# BlueNRG1 register map
Vendor: STMicroelectronics; Series: BlueNRG1; File version: 2.2.1
ARM 32-bit Cortex-M0 Microcontroller based device, CPU clock up to 32MHz
CPU: CM0 r0p0, little endian, no MPU, no FPU, 2 interrupt priority bits
Registers are 32-bit, read-write, reset 0x0 unless marked. A register's access mark holds for its fields unless they carry their own. Offsets are from the block's base; lines under a group give offsets from that group; [hi:lo] are bit positions; {n}, {i} and the like mark numbered series; 'fields as' and 'values as' point back to an identical list; <NAME> marks a mode.

## Memory map
0x10000000 ROM_INFO size 0x800 — ROM information
0x40000000 GPIO size 0x1000 — GPIO Controller
0x40100000 FLASH size 0x1000 — Flash Controller
0x40200000 SYSTEM_CTRL size 0x1000 — System controller
0x40300000 UART size 0x1000
0x40400000 SPI size 0x1000 — Serial peripheral interface
0x40700000 WDG size 0x1000 — Watchdog
0x40800000 ADC size 0x1000
0x40900000 CKGEN_SOC size 0x1000 — Clock Gen SOC
0x40A00000 I2C2 size 0x1000
0x40B00000 I2C1 size 0x1000
0x40C00000 AHBUPCONV size 0x1000 — AHB up/down converter converter
0x40D00000 MFT1 size 0x1000
0x40E00000 MFT2 size 0x1000
0x40F00000 RTC size 0x1000 — Real-Time Counter
0x48000000 BLUE_CTRL size 0x1000 — BLUE Controller
0x48100000 CKGEN_BLE size 0x1000 — Clock Gen BLE
0xA0000000 DMA size 0x8
0xA0000008 DMA_CH0 size 0x10 — DMA channel
0xA000001C DMA_CH1 size 0x10
0xA0000030 DMA_CH2 size 0x10
0xA0000044 DMA_CH3 size 0x10
0xA0000058 DMA_CH4 size 0x10
0xA000006C DMA_CH5 size 0x10
0xA0000080 DMA_CH6 size 0x10
0xA0000094 DMA_CH7 size 0x10
0xB0000000 RNG size 0x1000
0xC0000000 PKA size 0x1000

## Interrupts
0 GPIO — GPIO bus interrupt
1 NVM (FLASH) — Non-volatile memory (Flash) controller interrupt
4 UART — UART interrupt
5 SPI — SPI interrupt
6 BLUE_CTRL — BLUE controller interrupt
7 WDG — Watchdog interrupt
13 ADC — ADC interrupt
14 I2C2 — I2C 2 interrupt
15 I2C1 — I2C 1 interrupt
17 MFT1A (MFT1) — Multi functional timer MFT1 interrupt A
18 MFT1B (MFT1) — Multi functional timer MFT1 interrupt B
19 MFT2A (MFT2) — Multi functional timer MFT2 interrupt A
20 MFT2B (MFT2) — Multi functional timer MFT2 interrupt B
21 RTC — RTC interrupt
22 PKA — PKA interrupt
23 DMA — DMA interrupt

## GPIO — GPIO Controller
Base 0x40000000
0x00 DATA (reset mask 0x3FFFFFF) — IO0 to IO14 data value.<p>Writing to a bit will drive the written value on the corresponding IO when it is configured in GPIO mode and the output direction. Reading a bit indicates the pin value</p>
0x04 OEN (reset mask 0x3FFFFFF) — GPIO output enable register (1 bit per GPIO).<ul><li>0: input mode.</li><li>1: output mode</li></ul>
0x08 PE reset 0x3FFFFFF (reset mask 0x3FFFFFF) — Pull enable (1 bit per IO).<ul><li>0: pull disabled.</li><li>1: pull enabled</li></ul>
0x0C DS (reset mask 0x3FFFFFF) — IO driver strength (1 bit per IO).<ul><li>0: 2mA.</li><li>1: 4 mA</li></ul>
0x10 IS (reset mask 0x3FFFFFF) — Interrupt sense register (1 bit per IO).<ul><li>0: edge detection.</li><li>1: level detection</li></ul>
0x14 IBE (reset mask 0x3FFFFFF) — Interrupt edge register (1 bit per IO).<ul><li>0: single edge.</li><li>1: both edges</li></ul>
0x18 IEV (reset mask 0x3FFFFFF) — Interrupt event register (1 bit per IO).<ul><li>0: falling edge or low level.</li><li>1: rising edge or high level</li></ul>
0x1C IE (reset mask 0x3FFFFFF) — Interrupt mask register (1 bit per IO).<ul><li>0: interrupt disabled.</li><li>1: interrupt enabled.</li></ul>
0x20 RIS ro (reset mask 0x3FFFFFF) — Raw interrupt status register (1 bit per IO)
0x24 MIS ro (reset mask 0x3FFFFFF) — Masked interrupt status register (1 bit per IO)
0x28 IC wo (reset mask 0x3FFFFFF) write-1-clears — Interrupt clear register (1 bit per IO).<ul><li>0: no effect.</li><li>1: clear interrupt</li></ul>
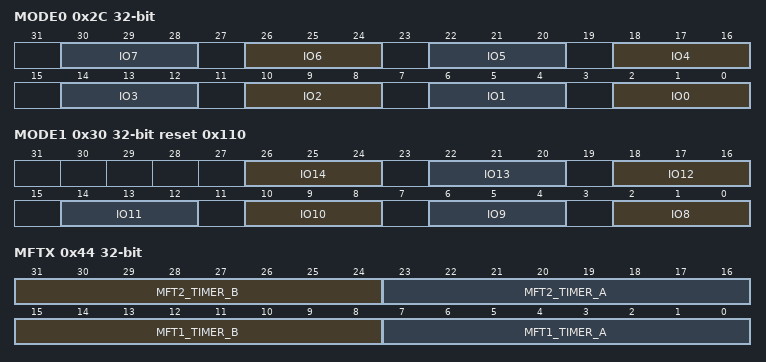
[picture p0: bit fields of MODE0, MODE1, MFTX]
0x2C MODE0 — Select mode for IO0 to IO7.<ul><li>000b: GPIO mode.</li><li>001b: Serial1 mode.</li><li>100b: Serial0 mode.</li><li>101b: Microphone/ADC mode.</li></ul>
  [all] fields
    0=GPIO_MODE; 1=SERIAL1_MODE; 2=STANDALONE_MODE; 3=BLUE_MODE (BLE mode); 4=SERIAL0_MODE; 5=MICROPHONE_ADC_MODE (ADC mode for microphone)
  [4n+2:4n] IO{n} (n=0..7) — IO{n} mode
0x30 MODE1 reset 0x110 — Select mode for IO8 to IO14.<ul><li>000b: GPIO mode.</li><li>001b: Serial1 mode.</li><li>100b: Serial0 mode.</li><li>101b: Microphone/ADC mode.</li></ul>
  [all] fields
    values as the fields of MODE0
  [4n-30:4n-32] IO{n} (n=8..14) — IO{n} mode
0x3C DATS (reset mask 0x3FFFFFF) — Set some bits of DATA when in GPIO mode without affecting the others (1 bit per IO).<ul><li>0: no effect.</li><li>1: set at 1 the bit</li></ul>
0x40 DATC (reset mask 0x3FFFFFF) — Clear some bits of DATA when in GPIO mode without affecting the others (1 bit per IO).<ul><li>0: no effect.</li><li>1: clear at 0 the bit</li></ul>
0x44 MFTX — Select the IO to be used as capture input for the MFTX timers
  [all] fields
    {v}=IO{v} (v=0..25)
  [31:24] MFT2_TIMER_B — Selects which IO must be used as input pin TnB for the MFT2 peripheral. Only mode 2 and mode 4.<ul><li>0x00: IO0.</li><li>0x01: IO1</li><li>0x02: IO2</li><li>...</li><li>0x0E: IO14</li></ul>
  [23:16] MFT2_TIMER_A — Selects which IO must be used as input pin TnA for the MFT2 peripheral. Only mode 2 and mode 4.<ul><li>0x00: IO0.</li><li>0x01: IO1</li><li>0x02: IO2</li><li>...</li><li>0x0E: IO14</li></ul>
  [15:8] MFT1_TIMER_B — Selects which IO must be used as input pin TnB for the MFT1 peripheral. Only mode 2 and mode 4.<ul><li>0x00: IO0.</li><li>0x01: IO1</li><li>0x02: IO2</li><li>...</li><li>0x0E: IO14</li></ul>
  [7:0] MFT1_TIMER_A — Selects which IO must be used as input pin TnA for the MFT1 peripheral. Only mode 2 and mode 4.<ul><li>0x00: IO0.</li><li>0x01: IO1</li><li>0x02: IO2</li><li>...</li><li>0x0E: IO14</li></ul>

## Licence text in the file
THIS SOFTWARE IS PROVIDED BY THE COPYRIGHT HOLDERS AND CONTRIBUTORS "AS IS" AND ANY EXPRESS OR IMPLIED WARRANTIES, INCLUDING, BUT NOT LIMITED TO, THE IMPLIED WARRANTIES OF MERCHANTABILITY AND FITNESS FOR A PARTICULAR PURPOSE ARE DISCLAIMED. IN NO EVENT SHALL THE COPYRIGHT HOLDER OR CONTRIBUTORS BE LIABLE FOR ANY DIRECT, INDIRECT, INCIDENTAL, SPECIAL, EXEMPLARY, OR CONSEQUENTIAL DAMAGES (INCLUDING, BUT NOT LIMITED TO, PROCUREMENT OF SUBSTITUTE GOODS OR SERVICES; LOSS OF USE, DATA, OR PROFITS; OR BUSINESS INTERRUPTION) HOWEVER CAUSED AND ON ANY THEORY OF LIABILITY, WHETHER IN CONTRACT, STRICT LIABILITY, OR TORT (INCLUDING NEGLIGENCE OR OTHERWISE) ARISING IN ANY WAY OUT OF THE USE OF THIS SOFTWARE, EVEN IF ADVISED OF THE POSSIBILITY OF SUCH DAMAGE.
